# Cortex_M7 register map
Vendor: Arm Ltd.; Series: ARMv7E-M; File version: 1.0.0
CPU: CM7 r0p0, little endian, MPU, FPU, double-precision FPU, DSP, 8 interrupt priority bits
Registers are 32-bit, read-write, reset 0x0 unless marked. A register's access mark holds for its fields unless they carry their own. Offsets are from the block's base; [hi:lo] are bit positions; {n}, {i} and the like mark numbered series.

## TPIU — Trace Port Interface Unit: drives the ITM/DWT/ETM trace out through the parallel trace port or the single-wire SWO pin (Manchester or UART/NRZ). ACPR sets the SWO baud rate, SPPR the pin protocol, FFCR the formatter.
Base 0xE0040000
0x00 SSPSR ro — Supported Parallel Port Size Register: bit n-1 set = a trace port width of n bits is supported. Read-only.
  [31:0] SWIDTH — Bit n-1 set = a trace port width of n bits is supported.
0x04 CSPSR — Current Parallel Port Size Register: one-hot, bit n-1 = width n; must be 1 (bit 0) for SWO.
  [31:0] CWIDTH — One-hot current port width: bit n-1 = n bits. 1 = single-bit (SWO).
0x10 ACPR — Asynchronous Clock Prescaler Register: SWO baud rate = TRACECLKIN / (PRESCALER + 1).
  [12:0] PRESCALER — SWO clock divider: baud rate = TRACECLKIN / (PRESCALER + 1). For example 4 MHz SWO from 200 MHz: PRESCALER = 49.
0xF0 SPPR — Selected Pin Protocol Register: parallel trace port, SWO Manchester or SWO NRZ (UART).
  [1:0] TXMODE — Pin protocol: 0 = parallel trace port, 1 = SWO Manchester, 2 = SWO NRZ (UART-like, the common choice), 3 = reserved.
    0=Parallel trace port; 1=SWO_Manchester (Serial wire output, Manchester encoding); 2=SWO_NRZ (Serial wire output, NRZ (UART) encoding)
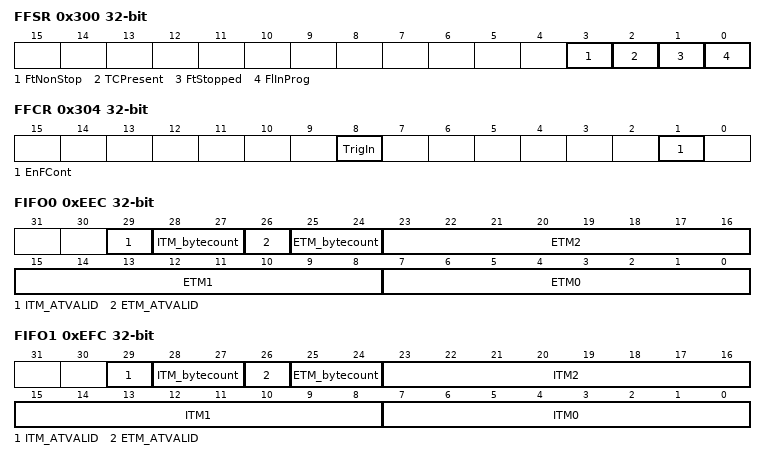
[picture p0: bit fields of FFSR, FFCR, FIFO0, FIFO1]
0x300 FFSR ro — Formatter and Flush Status Register.
  [3] FtNonStop — Formatter cannot be stopped (reads 1).
  [2] TCPresent — TRACECTL pin present: 1 = the trace port has a TRACECTL signal.
  [1] FtStopped — Formatter stopped (RAZ on cores whose formatter cannot stop).
  [0] FlInProg — Flush in progress.
0x304 FFCR — Formatter and Flush Control Register: enable continuous formatting (needed when the ETM and ITM share the port), manual flush, trigger indication.
  [8] TrigIn — Indicate a trigger on the TRIGIN input in the formatted stream (reads 1).
  [1] EnFCont — Enable continuous formatting: 1 = frames are always formatted with source IDs (required when the ETM and ITM share the trace port; must be 0 for ITM-only SWO to get raw ITM packets).
0x308 FSCR ro — Formatter Synchronization Counter Register: how often the formatter inserts a synchronization sequence.
  [11:0] CycCount — Formatter synchronization interval in cycles (0 = disabled). See the CoreSight TPIU specification.
0xEE8 TRIGGER ro — Integration register: the current state of the TRIGIN input.
  [0] TRIGGER — Current state of the TRIGIN input.
0xEEC FIFO0 ro — Integration Test FIFO Data 0: ETM data bytes and ATB valid/byte-count flags (integration mode).
  [29] ITM_ATVALID
  [28:27] ITM_bytecount — Number of valid ITM bytes - 1.
  [26] ETM_ATVALID
  [25:24] ETM_bytecount — Number of valid ETM bytes - 1.
  [23:16] ETM2 — ETM ATB data byte 2.
  [15:8] ETM1 — ETM ATB data byte 1.
  [7:0] ETM0 — ETM ATB data byte 0.
0xEF0 ITATBCTR2 ro — Integration Test ATB Control 2: ATREADY/AFVALID outputs to the ATB masters (integration mode).
  [0] ATREADY2 — ATB interface 2 ATREADY (integration).
0xEF8 ITATBCTR0 ro — Integration Test ATB Control 0: ATVALID/AFREADY inputs from the ATB masters (integration mode).
  [0] ATREADY2 — ATB interface 2 ATREADY (integration).
0xEFC FIFO1 ro — Integration Test FIFO Data 1: ITM data bytes and ATB flags (integration mode).
  [29] ITM_ATVALID
  [28:27] ITM_bytecount — Number of valid ITM bytes - 1.
  [26] ETM_ATVALID
  [25:24] ETM_bytecount — Number of valid ETM bytes - 1.
  [23:16] ITM2 — ITM ATB data byte 2.
  [15:8] ITM1 — ITM ATB data byte 1.
  [7:0] ITM0 — ITM ATB data byte 0.
0xF00 ITCTRL — Integration Mode Control Register.
  [1:0] Mode — Integration mode: 0 = normal operation, 1 = integration test mode (the IT* registers drive/observe the ATB and trace port).
0xFA0 CLAIMSET — Claim Tag Set Register: read = which claim bits are implemented, write 1 = set a claim bit. Lets a debugger and software signal ownership of the TPIU.
0xFA4 CLAIMCLR — Claim Tag Clear Register: read = current claim tag, write 1 = clear a bit.
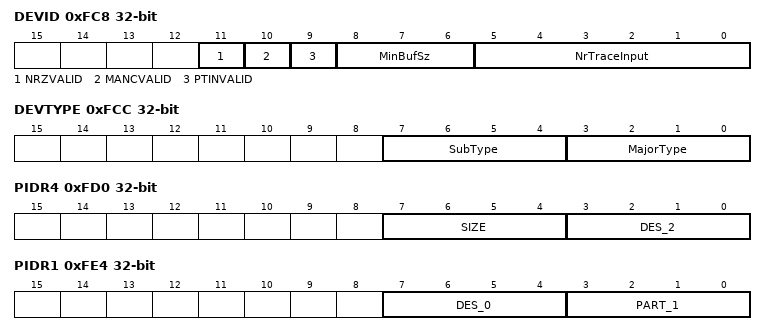
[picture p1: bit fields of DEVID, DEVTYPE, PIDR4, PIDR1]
0xFC8 DEVID ro — Device Configuration Register: number of trace inputs, FIFO size and which pin protocols are supported. Read-only.
  [11] NRZVALID — 1 = SWO NRZ (UART) encoding is supported.
  [10] MANCVALID — 1 = SWO Manchester encoding is supported.
  [9] PTINVALID — 1 = the parallel trace port is NOT supported (SWO only).
  [8:6] MinBufSz — Minimum input buffer size, log2 words (2 = 4 words on Cortex-M3/M4/M7).
  [5:0] NrTraceInput — Number of ATB trace inputs (implementation-defined encoding, see the core TRM; Cortex-M cores with an ETM have two: ETM and ITM).
0xFCC DEVTYPE ro — Device Type Register: 0x11 (trace sink, trace port). Read-only.
  [7:4] SubType — Sub type: 1 = trace port (TPIU).
  [3:0] MajorType — Major type: 1 = trace sink.
0xFD0 PIDR4 ro — Peripheral Identification Register 4: JEP106 continuation code and component size.
  [7:4] SIZE — Log2 of the number of 4 KB blocks the component occupies (0 = one block).
  [3:0] DES_2 — JEP106 continuation code of the designer (Arm: 0x4).
{0xFC0+4i} PIDR{i} ro (i=5..7) — Peripheral Identification Register {i} (reserved, reads as zero).
0xFE0 PIDR0 ro — Peripheral Identification Register 0: part number bits [7:0].
  [7:0] PART_0 — Part number bits [7:0].
0xFE4 PIDR1 ro — Peripheral Identification Register 1: part number bits [11:8] and designer bits [3:0].
  [7:4] DES_0 — JEP106 identity code bits [3:0] of the designer.
  [3:0] PART_1 — Part number bits [11:8].
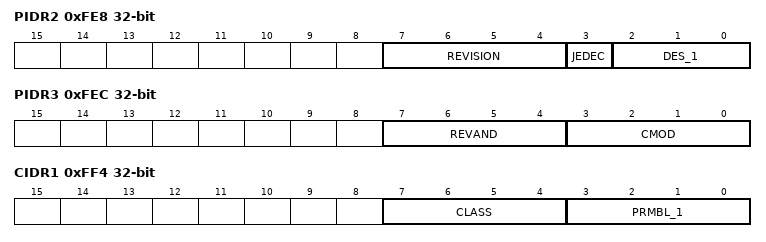
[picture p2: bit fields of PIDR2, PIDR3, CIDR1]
0xFE8 PIDR2 ro — Peripheral Identification Register 2: designer bits [6:4], JEDEC flag and revision.
  [7:4] REVISION — Component major revision.
  [3] JEDEC — Always 1: the designer ID is a JEDEC JEP106 code.
  [2:0] DES_1 — JEP106 identity code bits [6:4] of the designer.
0xFEC PIDR3 ro — Peripheral Identification Register 3: customer modified and minor revision.
  [7:4] REVAND — Minor revision (metal fix) number.
  [3:0] CMOD — Customer Modified: 0 if the component has not been modified by the integrator.
0xFF0 CIDR0 ro — Component Identification Register 0: preamble byte 0 (0x0D).
  [7:0] PRMBL_0 — Preamble, reads as 0x0D.
0xFF4 CIDR1 ro — Component Identification Register 1: component class and preamble.
  [7:4] CLASS — Component class: 0x1 ROM table, 0x9 CoreSight component, 0xE generic IP, 0xF CoreLink/PrimeCell.
  [3:0] PRMBL_1 — Preamble, reads as 0x0.
0xFF8 CIDR2 ro — Component Identification Register 2: preamble byte 2 (0x05).
  [7:0] PRMBL_2 — Preamble, reads as 0x05.
0xFFC CIDR3 ro — Component Identification Register 3: preamble byte 3 (0xB1).
  [7:0] PRMBL_3 — Preamble, reads as 0xB1.
